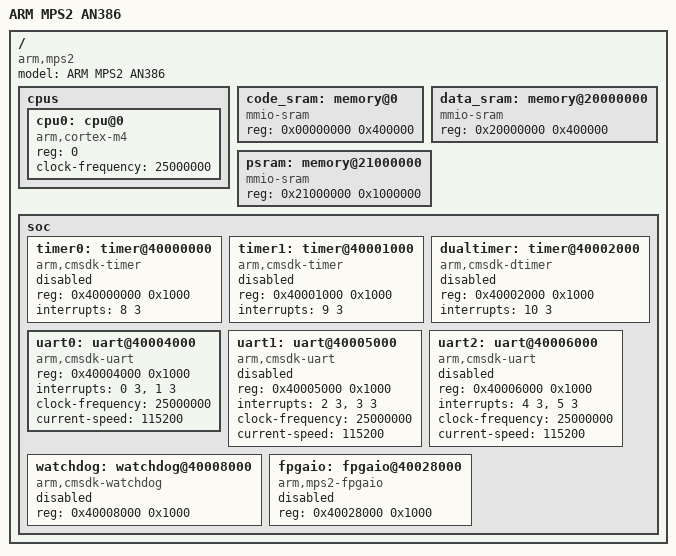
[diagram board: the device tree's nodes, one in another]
/*
 * mps2_an386.dts — Device Tree Source for ARM MPS2 AN386 (QEMU emulation)
 *
 * Describes the hardware modelled by QEMU's `mps2-an386` machine.
 * Compile with dtc: dtc -I dts -O dtb -o mps2_an386.dtb mps2_an386.dts
 */

/dts-v1/;

/ {
    #address-cells = <1>;
    #size-cells = <1>;
    model = "ARM MPS2 AN386";
    compatible = "arm,mps2", "arm,mps2-an386";

    /* ---------------------------------------------------------------
     * CPU — single Cortex-M4
     * ------------------------------------------------------------- */
    cpus {
        #address-cells = <1>;
        #size-cells = <0>;

        cpu0: cpu@0 {
            compatible = "arm,cortex-m4";
            device_type = "cpu";
            reg = <0>;
            clock-frequency = <25000000>;  /* 25 MHz fixed */
        };
    };

    /* ---------------------------------------------------------------
     * Memory
     * ------------------------------------------------------------- */
    code_sram: memory@0 {
        compatible = "mmio-sram";
        reg = <0x00000000 0x400000>;   /* 4MB ZBT SSRAM1 (code) */
    };

    data_sram: memory@20000000 {
        compatible = "mmio-sram";
        reg = <0x20000000 0x400000>;   /* 4MB ZBT SSRAM2/3 (data) */
    };

    psram: memory@21000000 {
        compatible = "mmio-sram";
        reg = <0x21000000 0x1000000>;  /* 16MB PSRAM */
    };

    /* ---------------------------------------------------------------
     * CMSDK APB peripherals
     * ------------------------------------------------------------- */
    soc {
        #address-cells = <1>;
        #size-cells = <1>;
        ranges;

        timer0: timer@40000000 {
            compatible = "arm,cmsdk-timer";
            reg = <0x40000000 0x1000>;
            interrupts = <8 3>;
            status = "disabled";
        };

        timer1: timer@40001000 {
            compatible = "arm,cmsdk-timer";
            reg = <0x40001000 0x1000>;
            interrupts = <9 3>;
            status = "disabled";
        };

        dualtimer: timer@40002000 {
            compatible = "arm,cmsdk-dtimer";
            reg = <0x40002000 0x1000>;
            interrupts = <10 3>;
            status = "disabled";
        };

        uart0: uart@40004000 {
            compatible = "arm,cmsdk-uart";
            reg = <0x40004000 0x1000>;
            interrupts = <0 3>, <1 3>;   /* RX IRQ 0, TX IRQ 1 */
            clock-frequency = <25000000>;
            current-speed = <115200>;
            status = "okay";             /* console — QEMU stdio */
        };

        uart1: uart@40005000 {
            compatible = "arm,cmsdk-uart";
            reg = <0x40005000 0x1000>;
            interrupts = <2 3>, <3 3>;
            clock-frequency = <25000000>;
            current-speed = <115200>;
            status = "disabled";
        };

        uart2: uart@40006000 {
            compatible = "arm,cmsdk-uart";
            reg = <0x40006000 0x1000>;
            interrupts = <4 3>, <5 3>;
            clock-frequency = <25000000>;
            current-speed = <115200>;
            status = "disabled";
        };

        watchdog: watchdog@40008000 {
            compatible = "arm,cmsdk-watchdog";
            reg = <0x40008000 0x1000>;
            status = "disabled";
        };

        fpgaio: fpgaio@40028000 {
            compatible = "arm,mps2-fpgaio";
            reg = <0x40028000 0x1000>;   /* LEDs, buttons, counters */
            status = "disabled";
        };
    };
};
